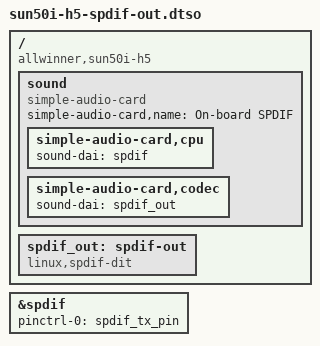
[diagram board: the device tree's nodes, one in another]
/dts-v1/;
/plugin/;

/ {
	compatible = "allwinner,sun50i-h5";

	fragment@0 {
		target = <&spdif>;
		__overlay__ {
			pinctrl-names = "default";
			pinctrl-0 = <&spdif_tx_pin>;
			status = "okay";
		};
	};

	fragment@1 {
		target-path = "/";
		__overlay__ {
			sound {
				compatible = "simple-audio-card";
				simple-audio-card,name = "On-board SPDIF";

				simple-audio-card,cpu {
					sound-dai = <&spdif>;
				};

				simple-audio-card,codec {
					sound-dai = <&spdif_out>;
				};
			};

			spdif_out: spdif-out {
				#sound-dai-cells = <0>;
				compatible = "linux,spdif-dit";
			};
		};
	};
};
